VERSION ""

NS_ :

BS_:

BU_: PC_SG BMS FC TMS CANmod LVC RPI

BO_ 109 InitiateCanFlash: 1 RPI
 SG_ ECU : 0|8@1+ (1,0) [0|2] "" FC,LVC,TMS

BO_ 110 LvSwitch: 6 PC_SG
 SG_ SwitchClose : 0|8@1+ (1,0) [0|1] ""  LVC

BO_ 3221225472 VECTOR__INDEPENDENT_SIG_MSG: 0 Vector__XXX
 SG_ FC_userBtnL : 0|1@1+ (1,0) [0|1] "" Vector__XXX
 SG_ FC_userBtnR : 0|1@1+ (1,0) [0|1] "" Vector__XXX

BO_ 123 SyncDbcHash: 8 LVC
 SG_ DbcHash : 0|64@1+ (1,0) [0|1] "" FC

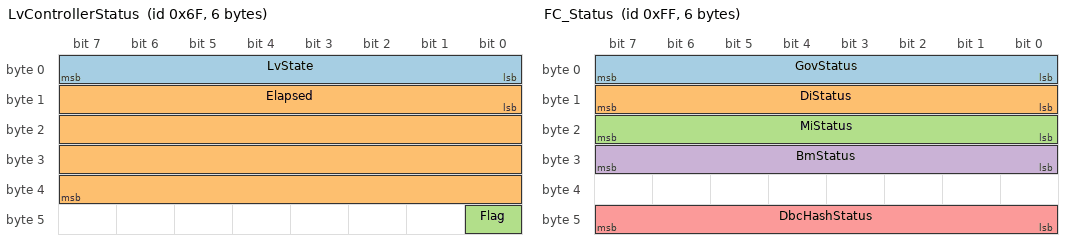
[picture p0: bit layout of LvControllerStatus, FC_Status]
BO_ 111 LvControllerStatus: 6 LVC
 SG_ LvState : 0|8@1+ (1,0) [0|1] ""  RPI
 SG_ Elapsed : 8|32@1- (1,0) [0|1] ""  RPI
 SG_ Flag : 40|1@1+ (1,0) [0|1] ""  RPI

BO_ 114 BrakeLight: 1 FC
 SG_ Enable : 0|1@1+ (1,0) [0|1] "" LVC

BO_ 113 SuspensionTravel34: 2 LVC
 SG_ STP3 : 0|8@1+ (1,0) [0|255] "" FC,RPI
 SG_ STP4 : 8|8@1+ (1,0) [0|255] "" FC,RPI

BO_ 255 FC_Status: 6 FC
 SG_ GovStatus : 0|8@1+ (1,0) [0|255] "" LVC, PC_SG
 SG_ DiStatus : 8|8@1+ (1,0) [0|255] "" LVC, PC_SG
 SG_ MiStatus : 16|8@1+ (1,0) [0|255] "" LVC, PC_SG
 SG_ BmStatus : 24|8@1+ (1,0) [0|255] "" LVC, PC_SG
 SG_ DbcHashStatus : 40|8@1+ (1,0) [0|255] "" LVC, PC_SG

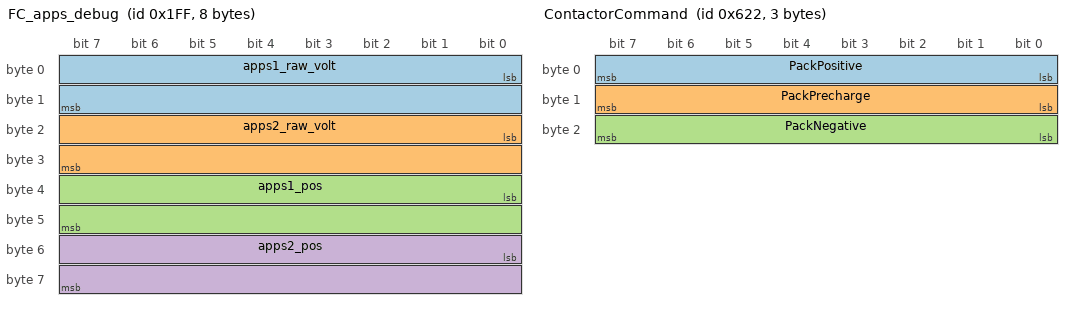
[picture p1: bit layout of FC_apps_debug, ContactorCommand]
BO_ 511 FC_apps_debug: 8 FC
 SG_ apps1_raw_volt : 0|16@1+ (0.001,0) [0|0] "volt"  PC_SG
 SG_ apps2_raw_volt : 16|16@1+ (0.001,0) [0|0] "volt"  PC_SG
 SG_ apps1_pos : 32|16@1+ (0.1,0) [0|0] "percent" PC_SG
 SG_ apps2_pos : 48|16@1+ (0.1,0) [0|0] "percent" PC_SG

BO_ 512 FC_debug: 8 FC
 SG_ FC_bpps : 32|12@1+ (1,0) [0|4095] ""  PC_SG
 SG_ FC_steeringAngle : 48|12@1+ (1,0) [0|4095] ""  PC_SG

BO_ 256 FC_cmd: 1 PC_SG
 SG_ FC_readyToDriveSpeaker : 1|1@1+ (1,0) [0|1] ""  FC
 SG_ FC_brakeLight : 0|1@1+ (1,0) [0|1] ""  FC

BO_ 1570 ContactorCommand: 3 FC
 SG_ PackPositive : 0|8@1+ (1,0) [0|0] ""  BMS,LVC
 SG_ PackPrecharge : 8|8@1+ (1,0) [0|0] ""  BMS,LVC
 SG_ PackNegative : 16|8@1+ (1,0) [0|0] ""  BMS,LVC

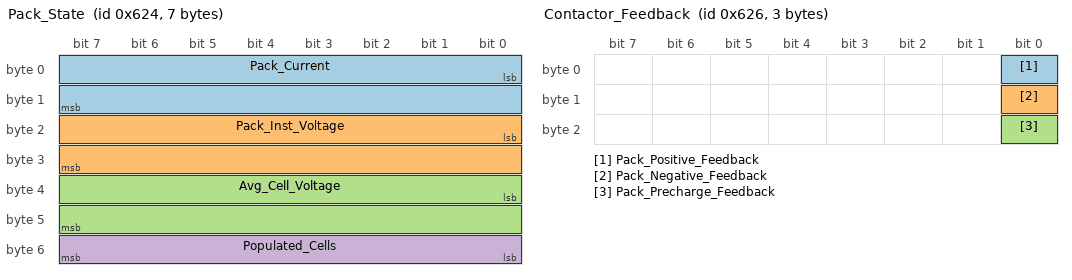
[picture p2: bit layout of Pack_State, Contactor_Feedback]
BO_ 1572 Pack_State: 7 BMS
 SG_ Pack_Current : 0|16@1+ (0.1,0) [0|0] "Amps"  FC
 SG_ Pack_Inst_Voltage : 16|16@1+ (0.1,0) [0|0] "Volts"  FC
 SG_ Avg_Cell_Voltage : 32|16@1+ (0.0001,0) [0|0] "Volts"  FC
 SG_ Populated_Cells : 48|8@1+ (1,0) [0|0] "Num"  FC

BO_ 1571 Pack_Current_Limits: 4 BMS
 SG_ Pack_CCL : 0|16@1+ (1,0) [0|0] "Amps"  FC
 SG_ Pack_DCL : 16|16@1+ (1,0) [0|0] "Amps"  FC

BO_ 1573 Pack_SOC: 3 BMS
 SG_ Pack_SOC : 0|8@1+ (0.5,0) [0|0] "Percent"  FC
 SG_ Maximum_Pack_Voltage : 8|16@1+ (0.1,0) [0|0] "Volts"  FC

BO_ 1574 Contactor_Feedback: 3 BMS
 SG_ Pack_Positive_Feedback : 0|1@1+ (1,0) [0|1] ""  FC
 SG_ Pack_Negative_Feedback : 8|1@1+ (1,0) [0|1] ""  FC
 SG_ Pack_Precharge_Feedback : 16|1@1+ (1,0) [0|1] ""  FC

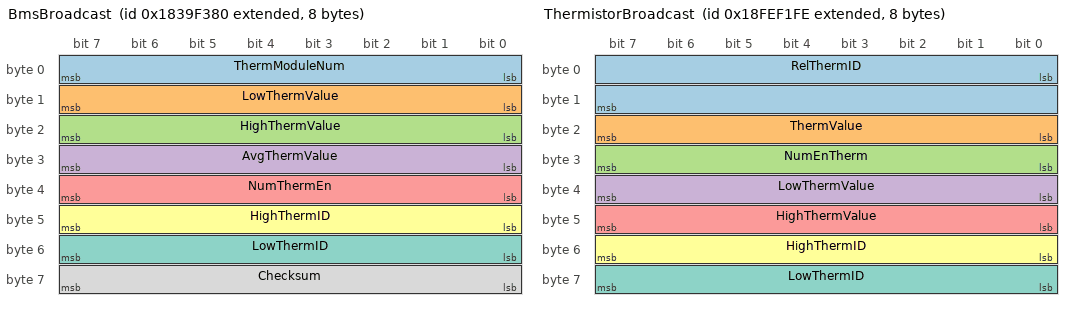
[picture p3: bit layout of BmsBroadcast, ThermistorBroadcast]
BO_ 2553934720 BmsBroadcast: 8 TMS
 SG_ ThermModuleNum : 0|8@1+ (1,0) [0|0] ""  BMS
 SG_ LowThermValue : 8|8@1- (1,0) [0|0] " C"  BMS
 SG_ HighThermValue : 16|8@1- (1,0) [0|0] " C"  BMS
 SG_ AvgThermValue : 24|8@1- (1,0) [0|0] " C"  BMS
 SG_ NumThermEn : 32|8@1+ (1,0) [0|0] ""  BMS
 SG_ HighThermID : 40|8@1+ (1,0) [0|0] ""  BMS
 SG_ LowThermID : 48|8@1+ (1,0) [0|0] ""  BMS
 SG_ Checksum : 56|8@1+ (1,0) [0|0] ""  BMS

BO_ 2566844926 ThermistorBroadcast: 8 TMS
 SG_ RelThermID : 0|16@1+ (1,0) [0|0] ""  BMS
 SG_ ThermValue : 16|8@1- (1,0) [0|0] " C"  BMS
 SG_ NumEnTherm : 24|8@1- (1,0) [0|0] ""  BMS
 SG_ LowThermValue : 32|8@1- (1,0) [0|0] " C"  BMS
 SG_ HighThermValue : 40|8@1- (1,0) [0|0] " C"  BMS
 SG_ HighThermID : 48|8@1+ (1,0) [0|0] ""  BMS
 SG_ LowThermID : 56|8@1+ (1,0) [0|0] ""  BMS

BO_ 769 GnssStatus: 1 CANmod
 SG_ FixType : 0|3@1+ (1,0) [0|5] ""  FC
 SG_ Satellites : 3|5@1+ (1,0) [0|31] ""  FC

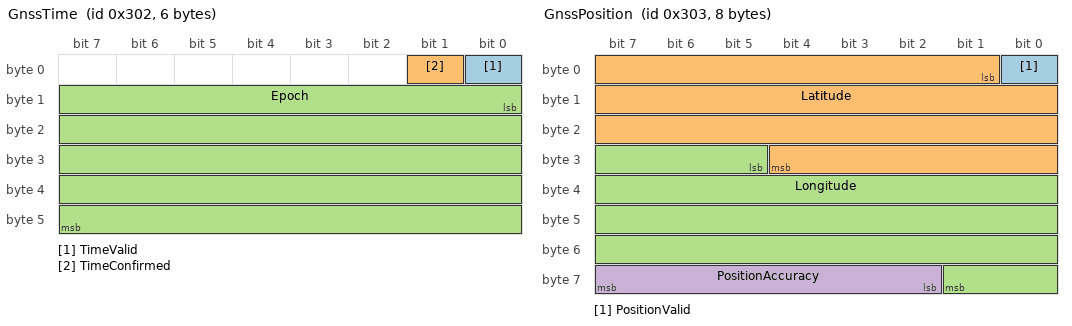
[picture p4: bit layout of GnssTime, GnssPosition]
BO_ 770 GnssTime: 6 CANmod
 SG_ TimeValid : 0|1@1+ (1,0) [0|1] ""  FC
 SG_ TimeConfirmed : 1|1@1+ (1,0) [0|1] ""  FC
 SG_ Epoch : 8|40@1+ (0.001,1577840400) [0|0] "sec"  FC

BO_ 771 GnssPosition: 8 CANmod
 SG_ PositionValid : 0|1@1+ (1,0) [0|1] ""  FC
 SG_ Latitude : 1|28@1+ (1E-006,-90) [-90|178.435455] "deg"  FC
 SG_ Longitude : 29|29@1+ (1E-006,-180) [-180|356.870911] "deg"  FC
 SG_ PositionAccuracy : 58|6@1+ (1,0) [0|63] "m"  FC

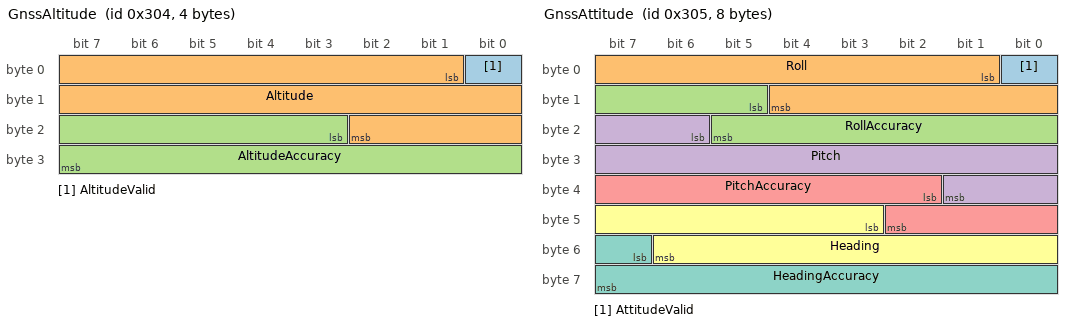
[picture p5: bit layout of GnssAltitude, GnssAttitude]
BO_ 772 GnssAltitude: 4 CANmod
 SG_ AltitudeValid : 0|1@1+ (1,0) [0|1] ""  FC
 SG_ Altitude : 1|18@1+ (0.1,-6000) [-6000|20000] "m"  FC
 SG_ AltitudeAccuracy : 19|13@1+ (1,0) [0|8000] "m"  FC

BO_ 773 GnssAttitude: 8 CANmod
 SG_ AttitudeValid : 0|1@1+ (1,0) [0|1] ""  FC
 SG_ Roll : 1|12@1+ (0.1,-180) [-180|180] "deg"  FC
 SG_ RollAccuracy : 13|9@1+ (0.1,0) [0|50] "deg"  FC
 SG_ Pitch : 22|12@1+ (0.1,-90) [-90|90] "deg"  FC
 SG_ PitchAccuracy : 34|9@1+ (0.1,0) [0|50] "deg"  FC
 SG_ Heading : 43|12@1+ (0.1,0) [0|360] "deg"  FC
 SG_ HeadingAccuracy : 55|9@1+ (0.1,0) [0|50] "deg"  FC

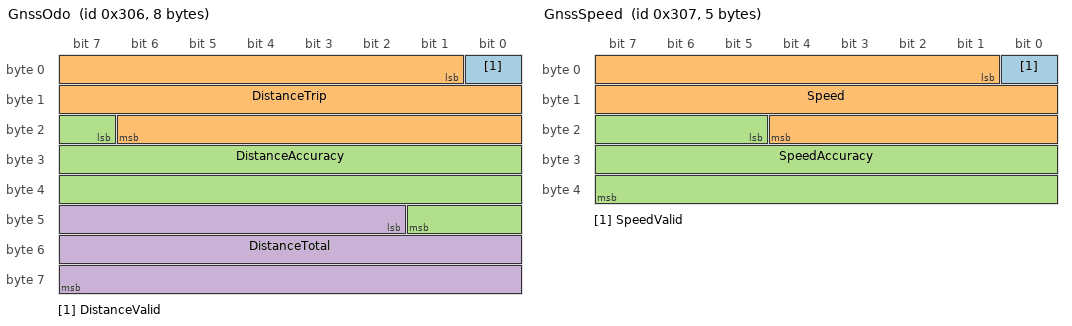
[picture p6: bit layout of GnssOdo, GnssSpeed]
BO_ 774 GnssOdo: 8 CANmod
 SG_ DistanceValid : 0|1@1+ (1,0) [0|1] ""  FC
 SG_ DistanceTrip : 1|22@1+ (1,0) [0|4194303] "m"  FC
 SG_ DistanceAccuracy : 23|19@1+ (1,0) [0|524287] "m"  FC
 SG_ DistanceTotal : 42|22@1+ (1,0) [0|4194303] "km"  FC

BO_ 775 GnssSpeed: 5 CANmod
 SG_ SpeedValid : 0|1@1+ (1,0) [0|1] ""  FC
 SG_ Speed : 1|20@1+ (0.001,0) [0|1048.575] "m/s"  FC
 SG_ SpeedAccuracy : 21|19@1+ (0.001,0) [0|524.287] "m/s"  FC

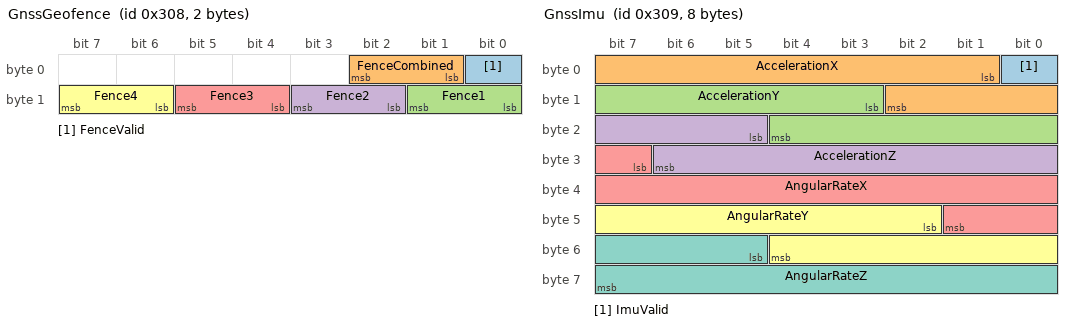
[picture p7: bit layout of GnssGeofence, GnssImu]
BO_ 776 GnssGeofence: 2 CANmod
 SG_ FenceValid : 0|1@1+ (1,0) [0|1] ""  FC
 SG_ FenceCombined : 1|2@1+ (1,0) [0|1] ""  FC
 SG_ Fence1 : 8|2@1+ (1,0) [0|1] ""  FC
 SG_ Fence2 : 10|2@1+ (1,0) [0|1] ""  FC
 SG_ Fence3 : 12|2@1+ (1,0) [0|1] ""  FC
 SG_ Fence4 : 14|2@1+ (1,0) [0|1] ""  FC

BO_ 777 GnssImu: 8 CANmod
 SG_ ImuValid : 0|1@1+ (1,0) [0|1] ""  FC
 SG_ AccelerationX : 1|10@1+ (0.125,-64) [-64|63.875] "m/s^2"  FC
 SG_ AccelerationY : 11|10@1+ (0.125,-64) [-64|63.875] "m/s^2"  FC
 SG_ AccelerationZ : 21|10@1+ (0.125,-64) [-64|63.875] "m/s^2"  FC
 SG_ AngularRateX : 31|11@1+ (0.25,-256) [-256|255.75] "deg/s"  FC
 SG_ AngularRateY : 42|11@1+ (0.25,-256) [-256|255.75] "deg/s"  FC
 SG_ AngularRateZ : 53|11@1+ (0.25,-256) [-256|255.75] "deg/s"  FC

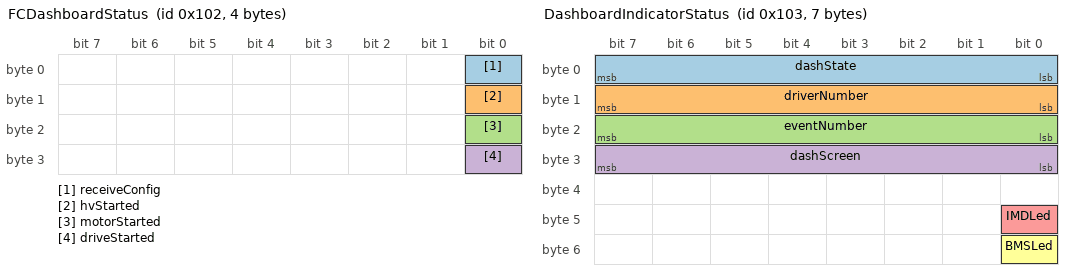
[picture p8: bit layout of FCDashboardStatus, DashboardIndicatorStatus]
BO_ 258 FCDashboardStatus: 4 FC
 SG_ receiveConfig      : 0|1@1+ (1,0) [0|1] "" Dash
 SG_ hvStarted          : 8|1@1+ (1,0) [0|1] ""  Dash
 SG_ motorStarted       : 16|1@1+ (1,0) [0|1] ""  Dash
 SG_ driveStarted       : 24|1@1+ (1,0) [0|1] ""  Dash

BO_ 259 DashboardIndicatorStatus: 7 Dash
 SG_ dashState           : 0|8@1+ (1,0) [0|1] "" FC
 SG_ driverNumber        : 8|8@1+ (1,0) [0|15] "" FC
 SG_ eventNumber         : 16|8@1+ (1,0) [0|15] "" FC
 SG_ dashScreen          : 24|8@1+ (1,0) [0|255] "" FC
 SG_ IMDLed			     : 40|1@1+ (1,0) [0|1] "" FC
 SG_ BMSLed  			 : 48|1@1+ (1,0) [0|1] "" FC

BO_ 260 RpiSpeed: 1 RPI
 SG_ speed : 0|8@1+ (1,0) [0|100] "" DASH

BO_ 261 dashboardTest: 1 Dash
 SG_ dashState           : 0|8@1+ (1,0) [0|1] "" FC

CM_ BO_ 3221225472 "This is a message for not used signals, created by Vector CANdb++ DBC OLE DB Provider.";
CM_ BO_ 1572 "This ID Transmits at 8 ms.";
CM_ BO_ 1571 "This ID Transmits at 8 ms.";
CM_ BO_ 1573 "This ID Transmits at 8 ms.";
CM_ BO_ 1574 "This ID Transmits at 8 ms.";
CM_ BO_ 2553934720 "Thermistor Module - BMS Broadcast";
CM_ SG_ 2553934720 ThermModuleNum "Thermistor Module Number";
CM_ BO_ 2566844926 "Thermistor General Broadcast";
CM_ SG_ 2566844926 RelThermID "Thermistor ID relative to all configured Thermistor Modules";
CM_ BO_ 769 "GNSS information";
CM_ SG_ 769 FixType "Fix type";
CM_ SG_ 769 Satellites "Number of satellites used";
CM_ BO_ 770 "GNSS time";
CM_ SG_ 770 TimeValid "Time validity";
CM_ SG_ 770 TimeConfirmed "Time confirmed";
CM_ SG_ 770 Epoch "Epoch time";
CM_ BO_ 771 "GNSS position";
CM_ SG_ 771 PositionValid "Position validity";
CM_ SG_ 771 Latitude "Latitude";
CM_ SG_ 771 Longitude "Longitude";
CM_ SG_ 771 PositionAccuracy "Accuracy of position";
CM_ BO_ 772 "GNSS altitude";
CM_ SG_ 772 AltitudeValid "Altitude validity";
CM_ SG_ 772 Altitude "Altitude";
CM_ SG_ 772 AltitudeAccuracy "Accuracy of altitude";
CM_ BO_ 773 "GNSS attitude";
CM_ SG_ 773 AttitudeValid "Attitude validity";
CM_ SG_ 773 Roll "Vehicle roll";
CM_ SG_ 773 RollAccuracy "Vehicle roll accuracy";
CM_ SG_ 773 Pitch "Vehicle pitch";
CM_ SG_ 773 PitchAccuracy "Vehicle pitch accuracy";
CM_ SG_ 773 Heading "Vehicle heading";
CM_ SG_ 773 HeadingAccuracy "Vehicle heading accuracy";
CM_ BO_ 774 "GNSS odometer";
CM_ SG_ 774 DistanceTrip "Distance traveled since last reset";
CM_ SG_ 774 DistanceAccuracy "Distance accuracy (1-sigma)";
CM_ SG_ 774 DistanceTotal "Distance traveled in total";
CM_ BO_ 775 "GNSS speed";
CM_ SG_ 775 SpeedValid "Speed valid";
CM_ SG_ 775 Speed "Speed m/s";
CM_ SG_ 775 SpeedAccuracy "Speed accuracy";
CM_ BO_ 776 "GNSS geofence(s)";
CM_ SG_ 776 FenceValid "Geofencing status";
CM_ SG_ 776 FenceCombined "Combined (logical OR) state of all geofences";
CM_ SG_ 776 Fence1 "Geofence 1 state";
CM_ SG_ 776 Fence2 "Geofence 2 state";
CM_ SG_ 776 Fence3 "Geofence 3 state";
CM_ SG_ 776 Fence4 "Geofence 4 state";
CM_ BO_ 777 "GNSS IMU";
CM_ SG_ 777 AccelerationX "X acceleration with a resolution of 0.125 m/s^2";
CM_ SG_ 777 AccelerationY "Y acceleration with a resolution of 0.125 m/s^2";
CM_ SG_ 777 AccelerationZ "Z acceleration with a resolution of 0.125 m/s^2";
CM_ SG_ 777 AngularRateX "X angular rate with a resolution of 0.25 deg/s";
CM_ SG_ 777 AngularRateY "Y angular rate with a resolution of 0.25 deg/s";
CM_ SG_ 777 AngularRateZ "Z angular rate with a resolution of 0.25 deg/s";
BA_DEF_  "BusType" STRING ;
BA_DEF_DEF_  "BusType" "CAN";
VAL_ 109 ECU 0 "FrontController" 1 "LvController" 2 "TMS";
VAL_ 111 LvState 0 "PWRUP_START" 1 "PWRUP_TSSI_ON" 2 "PWRUP_PERIPHERALS_ON" 3 "PWRUP_ACCUMULATOR_ON" 4 "PWRUP_MOTOR_PRECHARGE_ON" 5 "PWRUP_MOTOR_LV" 6 "PWRUP_MOTOR_PRECHARGE_OFF" 7 "PWRUP_SHUTDOWN_ON" 8 "MOTOR_CONTROLLER_SWITCH_SEQ" 9 "DCDC_ON" 10 "POWERTRAIN_PUMP_ON" 11 "POWERTRAIN_FAN_ON" 12 "POWERTRAIN_FAN_SWEEP" 13 "READY_TO_DRIVE" 14 "SHUTDOWN_DRIVER_WARNING" 15 "SHUTDOWN_PUMP_OFF" 16 "SHUTDOWN_FAN_OFF" 17 "SHUTDOWN_COMPLETE" 18 "PWRUP_CHECK_HASH_STATUS";
VAL_ 112 FcState 0 "PWRUP_START" 1 "HVIL_OPEN";
VAL_ 255 DbcHashStatus 0 "WAITING" 1 "VALID" 2 "INVALID";
VAL_ 255 VC_bmStatus 9 "err_running" 8 "bm_low_soc" 7 "hvil_interrupt" 6 "bm_running" 5 "precharge" 4 "init_precharge" 3 "bm_startup" 2 "bm_idle" 1 "bm_init" 0 "bm_unknown" ;
VAL_ 255 VC_diStatus 8 "di_error" 7 "di_running" 6 "hv_start_req" 5 "ready_to_drive_req" 4 "waiting_for_driver" 3 "di_startup" 2 "di_idle" 1 "di_sts_init" 0 "di_unknown" ;
VAL_ 255 VC_miStatus 7 "off" 6 "mi_sts_error" 5 "shutdown" 4 "running" 3 "ready" 2 "startup" 1 "sts_init" 0 "unknown" ;
VAL_ 255 VC_govStatus 8 "motor_run_error" 7 "hv_run_error" 6 "gov_di_error" 5 "motor_startup_error" 4 "hv_startup_error" 3 "gov_shutdown" 2 "gov_running" 1 "gov_startup" 0 "gov_init" ;
VAL_ 259 driverNumber 6 "Tyler" 5 "Nathan" 4 "Mubashir" 3 "Luca" 2 "Logan" 1 "Lin" 0 "Ada" ;
VAL_ 259 eventNumber 2 "Endurance" 1 "Skidpad" 0 "Launch" ;
VAL_ 259 dashState 5 "WaitBrakeStart" 4 "RequestedMotor" 3 "WaitRequestMotor" 2 "RequestedHV" 1 "WaitRequestHV" 0 "On" ;
